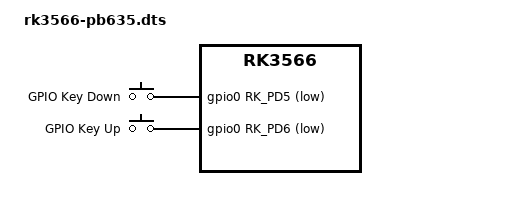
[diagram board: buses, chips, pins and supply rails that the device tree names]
/*
 * SPDX-License-Identifier:     GPL-2.0+
 *
 * (C) Copyright 2020 Rockchip Electronics Co., Ltd
 */

/dts-v1/;
#include "rk3568-evb.dts"
#include <dt-bindings/gpio/gpio.h>



/ {
	gpio_keys: gpio-keys {
		compatible = "gpio-keys";
		status = "okay";
		pinctrl-names = "default";
		pinctrl-0 = <&gpio_keys_gpio>;
		u-boot,dm-pre-reloc;

		DOWN {
			u-boot,dm-pre-reloc;
			label = "GPIO Key Down";
			linux,code = <KEY_DOWN>;
			gpios = <&gpio0 RK_PD5 GPIO_ACTIVE_LOW>;
		};

		UP {
			u-boot,dm-pre-reloc;
			label = "GPIO Key Up";
			linux,code = <KEY_UP>;
			gpios = <&gpio0 RK_PD6 GPIO_ACTIVE_LOW>;
		};
	};
};

&pinctrl {
	keys {
		gpio_keys_gpio: gpio-keys-gpio {
			rockchip,pins =
				<0 RK_PD5 RK_FUNC_GPIO &pcfg_pull_up>,
				<0 RK_PD6 RK_FUNC_GPIO &pcfg_pull_up>;
		};
	};
};

